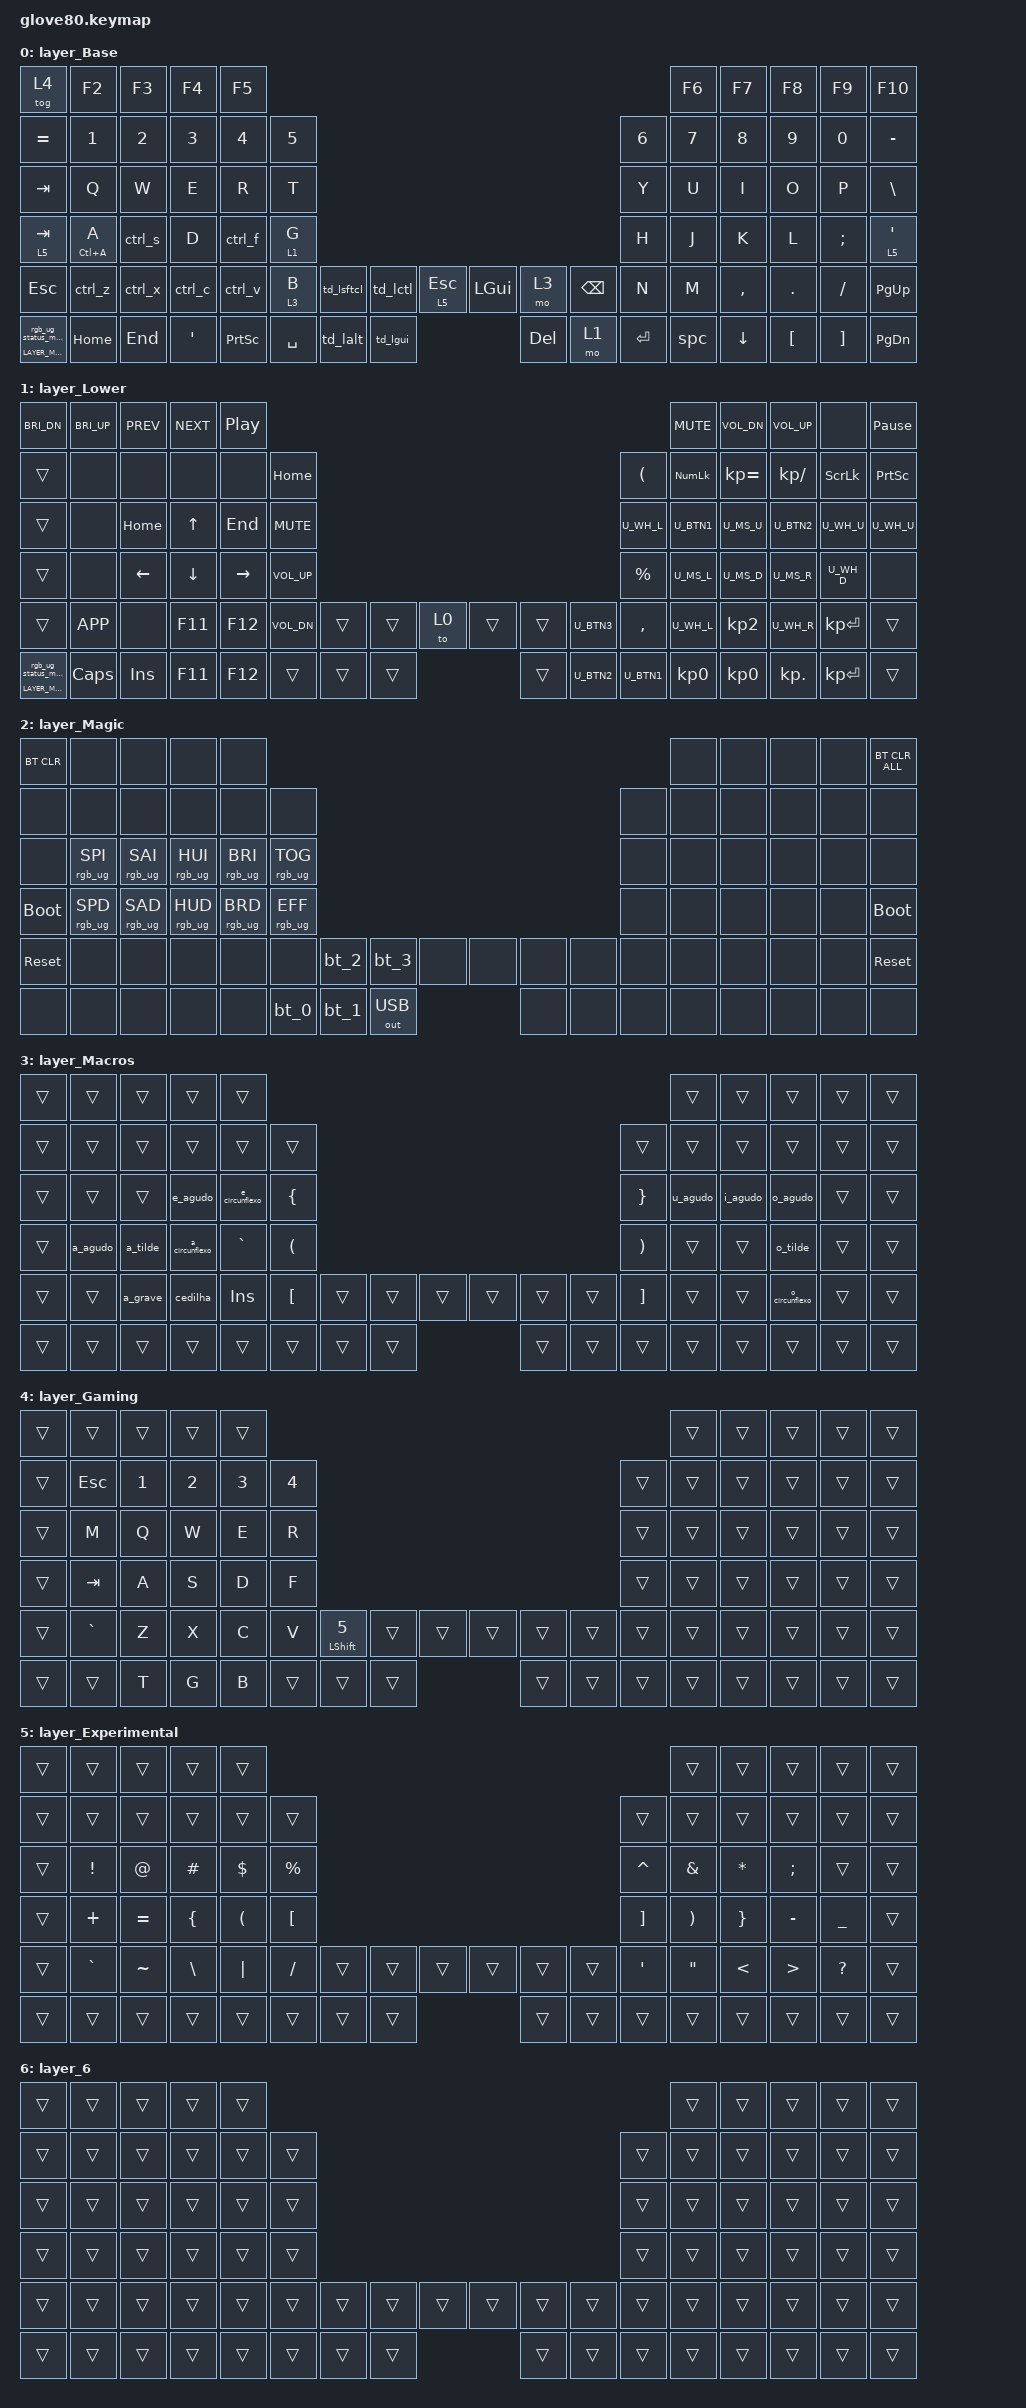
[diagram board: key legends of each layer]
/*
 * Copyright (c) 2020 The ZMK Contributors
 * Copyright (c) 2022 Innaworks Development Limited, trading as MoErgo
 * adding shenanigans
 * SPDX-License-Identifier: MIT
 */


/* THIS FILE WAS GENERATED BY GLOVE80 LAYOUT EDITOR
 *
 * This file was generated automatically. You may or may not want to
 * edit it directly.
 */
/* adding anything just to build it */
#include <behaviors.dtsi>
#include <dt-bindings/zmk/outputs.h>

/* Include behaviour includes needed by key binds - automatically generated */
#include <dt-bindings/zmk/keys.h>
#include <dt-bindings/zmk/ext_power.h>
#include <dt-bindings/zmk/bt.h>
#include <dt-bindings/zmk/rgb.h>
#include <dt-bindings/zmk/outputs.h>

#include "./zmk-nodefree-config/helper.h"
#include "./zmk-nodefree-config/keypos_def/keypos_glv80.h"

#include "./mouse.dtsi"


/* Automatically generated layer name #define */
#define LAYER_Base 0
#define LAYER_Lower 1
#define LAYER_Magic 2
#define LAYER_Macros 3
#define LAYER_Gaming 4
#define LAYER_Experimental 5
#define LAYER_6 6

/ {
    /* Glove80 system behavior & macros */
    behaviors {
        // For the "layer" key, it'd nice to be able to use it as either a shift or a toggle.
        // Configure it as a tap dance, so the first tap (or hold) is a &mo and the second tap is a &to
        lower: lower {
            compatible = "zmk,behavior-tap-dance";
            label = "LAYER_TAP_DANCE";
            #binding-cells = <0>;
            tapping-term-ms = <200>;
            bindings = <&mo LAYER_Lower>, <&to LAYER_Lower>;
        };
    };
};

/ {
    macros {
        rgb_ug_status_macro: rgb_ug_status_macro {
            label = "RGB_UG_STATUS";
            compatible = "zmk,behavior-macro";
            #binding-cells = <0>;
            bindings
                = <&rgb_ug RGB_STATUS>;
        };

        bt_0: bt_0 {
            label = "BT_0";
            compatible = "zmk,behavior-macro";
            #binding-cells = <0>;
            bindings
                = <&out OUT_BLE>,
                  <&bt BT_SEL 0>;
        };

        bt_1: bt_1 {
            label = "BT_1";
            compatible = "zmk,behavior-macro";
            #binding-cells = <0>;
            bindings
                = <&out OUT_BLE>,
                  <&bt BT_SEL 1>;
        };

        bt_2: bt_2 {
            label = "BT_2";
            compatible = "zmk,behavior-macro";
            #binding-cells = <0>;
            bindings
                = <&out OUT_BLE>,
                  <&bt BT_SEL 2>;
        };

        bt_3: bt_3 {
            label = "BT_3";
            compatible = "zmk,behavior-macro";
            #binding-cells = <0>;
            bindings
                = <&out OUT_BLE>,
                  <&bt BT_SEL 3>;
        };
    };
};

/ {
    magic: magic {
        compatible = "zmk,behavior-hold-tap";
        label = "MAGIC_HOLD_TAP";
        #binding-cells = <2>;
        flavor = "tap-preferred";
        tapping-term-ms = <200>;
        bindings = <&mo>, <&rgb_ug_status_macro>;
    };
};

    /* #define for key positions */
#define POS_LH_T1 52
#define POS_LH_T2 53
#define POS_LH_T3 54
#define POS_LH_T4 69
#define POS_LH_T5 70
#define POS_LH_T6 71
#define POS_LH_C1R2 15
#define POS_LH_C1R3 27
#define POS_LH_C1R4 39
#define POS_LH_C1R5 51
#define POS_LH_C2R1 4
#define POS_LH_C2R2 14
#define POS_LH_C2R3 26
#define POS_LH_C2R4 38
#define POS_LH_C2R5 50
#define POS_LH_C2R6 68
#define POS_LH_C3R1 3
#define POS_LH_C3R2 13
#define POS_LH_C3R3 25
#define POS_LH_C3R4 37
#define POS_LH_C3R5 49
#define POS_LH_C3R6 67
#define POS_LH_C4R1 2
#define POS_LH_C4R2 12
#define POS_LH_C4R3 24
#define POS_LH_C4R4 36
#define POS_LH_C4R5 48
#define POS_LH_C4R6 66
#define POS_LH_C5R1 1
#define POS_LH_C5R2 11
#define POS_LH_C5R3 23
#define POS_LH_C5R4 35
#define POS_LH_C5R5 47
#define POS_LH_C5R6 65
#define POS_LH_C6R1 0
#define POS_LH_C6R2 10
#define POS_LH_C6R3 22
#define POS_LH_C6R4 34
#define POS_LH_C6R5 46
#define POS_LH_C6R6 64
#define POS_RH_T1 57
#define POS_RH_T2 56
#define POS_RH_T3 55
#define POS_RH_T4 74
#define POS_RH_T5 73
#define POS_RH_T6 72
#define POS_RH_C1R2 16
#define POS_RH_C1R3 28
#define POS_RH_C1R4 40
#define POS_RH_C1R5 58
#define POS_RH_C2R1 5
#define POS_RH_C2R2 17
#define POS_RH_C2R3 29
#define POS_RH_C2R4 41
#define POS_RH_C2R5 59
#define POS_RH_C2R6 75
#define POS_RH_C3R1 6
#define POS_RH_C3R2 18
#define POS_RH_C3R3 30
#define POS_RH_C3R4 42
#define POS_RH_C3R5 60
#define POS_RH_C3R6 76
#define POS_RH_C4R1 7
#define POS_RH_C4R2 19
#define POS_RH_C4R3 31
#define POS_RH_C4R4 43
#define POS_RH_C4R5 61
#define POS_RH_C4R6 77
#define POS_RH_C5R1 8
#define POS_RH_C5R2 20
#define POS_RH_C5R3 32
#define POS_RH_C5R4 44
#define POS_RH_C5R5 62
#define POS_RH_C5R6 78
#define POS_RH_C6R1 9
#define POS_RH_C6R2 21
#define POS_RH_C6R3 33
#define POS_RH_C6R4 45
#define POS_RH_C6R5 63
#define POS_RH_C6R6 79

    /* Custom Defined Behaviors */
/ {
    #define CONFIG_BT_PERIPHERAL_PREF_MAX_INT=6;
#define CONFIG_ZMK_KSCAN_DEBOUNCE_PRESS_MS=0;
macros {
        #define COMPOSE_KEY F24

        #define COMPOSE_TAP_2(name, k1, k2) \
            name: name { \
                    label = #name; \
                    compatible = "zmk,behavior-macro"; \
                    #binding-cells = <0>; \
                    wait-ms = <10>; \
                    tap-ms = <10>; \
                    bindings \
                        = <&macro_tap     &kp COMPOSE_KEY &kp k1 &kp k2> \
                        ; \
                };
        // á
        COMPOSE_TAP_2(a_agudo, SQT, A)
        // é
        COMPOSE_TAP_2(e_agudo, SQT, E)
        // í
        COMPOSE_TAP_2(i_agudo, SQT, I)
        // ó
        COMPOSE_TAP_2(o_agudo, SQT, O)
        // ú
        COMPOSE_TAP_2(u_agudo, SQT, U)
        // cedilha
        COMPOSE_TAP_2(cedilha, SQT, C)
        // ã
        COMPOSE_TAP_2(a_tilde, TILDE, A)
        // õ
        COMPOSE_TAP_2(o_tilde, TILDE, O)
        // â
        COMPOSE_TAP_2(a_circunflexo, CARET, A)
        // ê
        COMPOSE_TAP_2(e_circunflexo, CARET, E)
        // ô
        COMPOSE_TAP_2(o_circunflexo, CARET, O)
        // à
        COMPOSE_TAP_2(a_grave, GRAVE, A)
    };
     behaviors {  
        ctrld: ctrld {
            compatible = "zmk,behavior-hold-tap";
            label = "ctrl_a";
            #binding-cells = <2>;          
            flavor = "tap-preferred";
            tapping-term-ms = <180>;
            bindings = <&kp>, <&kp>;
        };
        hl: homerow_layer {
		compatible = "zmk,behavior-hold-tap";
		label = "HOMEROW_LAYER";
		#binding-cells = <2>;
        tapping-term-ms = <250>;
        quick-tap-ms = <125>;
        global-quick-tap;
		flavor = "tap-preferred";
		bindings = <&mo>, <&kp>;
	};
	shift_tap_caps_word: behavior_shift_tap_caps_word {
		compatible = "zmk,behavior-caps-word";
		label = "SHIFT_TAP_CAPS_WORD";
		#binding-cells = <0>;
		continue-list = <UNDERSCORE MINUS BACKSPACE DELETE>;
		mods = <(MOD_LSFT | MOD_RSFT)>;
	};
    skq: sticky_key_quick_release {
        compatible = "zmk,behavior-sticky-key";
        label = "STICKY_KEY_QUICK_RELEASE";
        #binding-cells = <1>;
        bindings = <&kp>;
        release-after-ms = <1000>;
        quick-release;
        ignore-modifiers;
    };
    td_lsftcl: tap_dance_left_shift_caps_lock {
        compatible = "zmk,behavior-tap-dance";
        label = "TAP_DANCE_LEFT_SHIFT_CAPS_LOCK";
        #binding-cells = <0>;
        tapping-term-ms = <300>;
        bindings = <&kp LSHIFT>, <&kp CAPS>;
    };
    td_lsft: tap_dance_left_shift_caps_word {
        compatible = "zmk,behavior-tap-dance";
        label = "TAP_DANCE_LEFT_SHIFT_CAPS_WORD";
        #binding-cells = <0>;
        tapping-term-ms = <300>;
        bindings = <&skq LSHIFT>, <&shift_tap_caps_word>;
    };
    td_rsft: tap_dance_right_shift_caps_word {
        compatible = "zmk,behavior-tap-dance";
        label = "TAP_DANCE_RIGHT_SHIFT_CAPS_WORD";
        #binding-cells = <0>;
        tapping-term-ms = <300>;
        bindings = <&skq RSHIFT>, <&shift_tap_caps_word>;
    };
    td_lctl: tap_dance_left_ctrl {
        compatible = "zmk,behavior-tap-dance";
        label = "TAP_DANCE_LEFT_CTRL";
        #binding-cells = <0>;
        tapping-term-ms = <300>;
        bindings = <&skq LCTRL>, <&skq LS(LCTRL)>;
    };
    td_rctl: tap_dance_right_ctrl {
        compatible = "zmk,behavior-tap-dance";
        label = "TAP_DANCE_RIGHT_CTRL";
        #binding-cells = <0>;
        tapping-term-ms = <300>;
        bindings = <&skq RCTRL>, <&skq LS(RCTRL)>;
    };
    td_lalt: tap_dance_left_alt {
        compatible = "zmk,behavior-tap-dance";
        label = "TAP_DANCE_LEFT_ALT";
        #binding-cells = <0>;
        tapping-term-ms = <300>;
        bindings = <&skq LALT>, <&skq LS(LALT)>;
    };
    td_ralt: tap_dance_right_alt {
        compatible = "zmk,behavior-tap-dance";
        label = "TAP_DANCE_RIGHT_ALT";
        #binding-cells = <0>;
        tapping-term-ms = <300>;
        bindings = <&skq RALT>, <&skq LS(RALT)>;
    };
    td_lgui: tap_dance_left_gui {
        compatible = "zmk,behavior-tap-dance";
        label = "TAP_DANCE_LEFT_GUI";
        #binding-cells = <0>;
        tapping-term-ms = <300>;
        bindings = <&kp LGUI>, <&kp LS(LGUI)>;
    };
    spc: space_underscore {
        compatible = "zmk,behavior-mod-morph";
        label = "SPACE_UNDERSCORE";
        #binding-cells = <0>;
        bindings = <&kp SPACE>, <&kp UNDERSCORE>;
        mods = <(MOD_LSFT|MOD_RSFT)>;
        keep-mods = <(MOD_RSFT)>;
    };
        #define CTRLD_TAP(name, k1) \
            name: name { \
                    label = #name; \
                    compatible = "zmk,behavior-tap-dance"; \
                    #binding-cells = <0>; \
                    tapping-term-ms = <210>; \
                    bindings \
                        = <&ctrld LC(k1) k1 > \
                        ; \
            };
        CTRLD_TAP(ctrl_a, A)
        CTRLD_TAP(ctrl_c, C)
        CTRLD_TAP(ctrl_s, S)
        CTRLD_TAP(ctrl_x, X)
        CTRLD_TAP(ctrl_f, F)
        CTRLD_TAP(ctrl_v, V)
        CTRLD_TAP(ctrl_z, Z)
    };
};

    /* Automatically generated keymap */
/ {
    keymap {
        compatible = "zmk,keymap";


        layer_Base {
            bindings = <
               &tog 4          &kp F2   &kp F3   &kp F4     &kp F5                                                                                &kp F6     &kp F7    &kp F8    &kp F9             &kp F10
            &kp EQUAL          &kp N1   &kp N2   &kp N3     &kp N4   &kp N5                                                               &kp N6  &kp N7     &kp N8    &kp N9    &kp N0           &kp MINUS
              &kp TAB           &kp Q    &kp W    &kp E      &kp R    &kp T                                                                &kp Y   &kp U      &kp I     &kp O     &kp P            &kp BSLH
            &hl 5 TAB  &ctrld LC(A) A  &ctrl_s    &kp D    &ctrl_f  &hl 1 G                                                                &kp H   &kp J      &kp K     &kp L  &kp SEMI  &hl 5 SINGLE_QUOTE
              &kp ESC         &ctrl_z  &ctrl_x  &ctrl_c    &ctrl_v  &hl 3 B  &td_lsftcl  &td_lctl  &hl 5 ESC  &kp LGUI   &mo 3  &kp BSPC   &kp N   &kp M  &kp COMMA   &kp DOT  &kp FSLH           &kp PG_UP
 &magic LAYER_Magic 0        &kp HOME  &kp END  &kp SQT  &kp PSCRN            &kp SPACE  &td_lalt   &td_lgui   &kp DEL   &mo 1   &kp RET            &spc   &kp DOWN  &kp LBKT  &kp RBKT           &kp PG_DN
            >;
        };

        layer_Lower {
            bindings = <
         &kp C_BRI_DN  &kp C_BRI_UP      &kp C_PREV      &kp C_NEXT         &kp C_PP                                                                                       &kp C_MUTE  &kp C_VOL_DN  &kp C_VOL_UP            &none  &kp PAUSE_BREAK
               &trans         &none           &none           &none            &none      &kp HOME                                                   &kp LEFT_PARENTHESIS  &kp KP_NUM  &kp KP_EQUAL  &kp KP_SLASH  &kp SCROLLLOCK  &kp PRINTSCREEN
               &trans         &none        &kp HOME    &kp UP_ARROW          &kp END    &kp C_MUTE                                                    U_WH_L        U_BTN1        U_MS_U       U_BTN2       U_WH_U   U_WH_U
               &trans         &none  &kp LEFT_ARROW  &kp DOWN_ARROW  &kp RIGHT_ARROW  &kp C_VOL_UP                                                    &kp PERCENT   U_MS_L        U_MS_D       U_MS_R        U_WH_D      &none
               &trans     &kp K_APP           &none         &kp F11          &kp F12  &kp C_VOL_DN  &trans  &trans   &to 0  &trans  &trans  U_BTN3    &kp COMMA     U_WH_L        &kp KP_N2    U_WH_R     &kp KP_ENTER       &trans
 &magic LAYER_Magic 0      &kp CAPS         &kp INS         &kp F11          &kp F12                &trans  &trans  &trans  &trans  U_BTN2  U_BTN1             &kp KP_N0     &kp KP_N0    &kp KP_DOT    &kp KP_ENTER      &trans
            >;
        };

        layer_Magic {
            bindings = <
  &bt BT_CLR            &none            &none            &none            &none                                                                                  &none   &none   &none   &none  &bt BT_CLR_ALL
       &none            &none            &none            &none            &none            &none                                                         &none   &none   &none   &none   &none           &none
       &none  &rgb_ug RGB_SPI  &rgb_ug RGB_SAI  &rgb_ug RGB_HUI  &rgb_ug RGB_BRI  &rgb_ug RGB_TOG                                                         &none   &none   &none   &none   &none           &none
 &bootloader  &rgb_ug RGB_SPD  &rgb_ug RGB_SAD  &rgb_ug RGB_HUD  &rgb_ug RGB_BRD  &rgb_ug RGB_EFF                                                         &none   &none   &none   &none   &none     &bootloader
      &sys_reset            &none            &none            &none            &none            &none   &bt_2   &bt_3         &none   &none   &none   &none   &none   &none   &none   &none   &none          &sys_reset
       &none            &none            &none            &none            &none                    &bt_0   &bt_1  &out OUT_USB   &none   &none   &none           &none   &none   &none   &none           &none
            >;
        };

        layer_Macros {
            bindings = <
 &trans    &trans    &trans          &trans          &trans                                                                        &trans    &trans          &trans  &trans  &trans
 &trans    &trans    &trans          &trans          &trans    &trans                                                    &trans    &trans    &trans          &trans  &trans  &trans
 &trans    &trans    &trans        &e_agudo  &e_circunflexo  &kp LBRC                                                  &kp RBRC  &u_agudo  &i_agudo        &o_agudo  &trans  &trans
 &trans  &a_agudo  &a_tilde  &a_circunflexo       &kp GRAVE  &kp LPAR                                                  &kp RPAR    &trans    &trans        &o_tilde  &trans  &trans
 &trans    &trans  &a_grave        &cedilha         &kp INS  &kp LBKT  &trans  &trans  &trans  &trans  &trans  &trans  &kp RBKT    &trans    &trans  &o_circunflexo  &trans  &trans
 &trans    &trans    &trans          &trans          &trans            &trans  &trans  &trans  &trans  &trans  &trans              &trans    &trans          &trans  &trans  &trans
            >;
        };

        layer_Gaming {
            bindings = <
 &trans     &trans  &trans  &trans  &trans                                                                        &trans  &trans  &trans  &trans  &trans
 &trans    &kp ESC  &kp N1  &kp N2  &kp N3  &kp N4                                                        &trans  &trans  &trans  &trans  &trans  &trans
 &trans      &kp M   &kp Q   &kp W   &kp E   &kp R                                                        &trans  &trans  &trans  &trans  &trans  &trans
 &trans    &kp TAB   &kp A   &kp S   &kp D   &kp F                                                        &trans  &trans  &trans  &trans  &trans  &trans
 &trans  &kp GRAVE   &kp Z   &kp X   &kp C   &kp V  &mt LSHFT N5  &trans  &trans  &trans  &trans  &trans  &trans  &trans  &trans  &trans  &trans  &trans
 &trans     &trans   &kp T   &kp G   &kp B                &trans  &trans  &trans  &trans  &trans  &trans          &trans  &trans  &trans  &trans  &trans
            >;
        };

        layer_Experimental {
            bindings = <
 &trans     &trans     &trans    &trans    &trans                                                                          &trans    &trans     &trans     &trans  &trans
 &trans     &trans     &trans    &trans    &trans     &trans                                                     &trans    &trans    &trans     &trans     &trans  &trans
 &trans   &kp EXCL     &kp AT  &kp HASH  &kp DLLR  &kp PRCNT                                                  &kp CARET  &kp AMPS  &kp STAR   &kp SEMI     &trans  &trans
 &trans   &kp PLUS  &kp EQUAL  &kp LBRC  &kp LPAR   &kp LBKT                                                   &kp RBKT  &kp RPAR  &kp RBRC  &kp MINUS  &kp UNDER  &trans
 &trans  &kp GRAVE  &kp TILDE  &kp BSLH  &kp PIPE   &kp FSLH  &trans  &trans  &trans  &trans  &trans  &trans    &kp SQT   &kp DQT    &kp LT     &kp GT  &kp QMARK  &trans
 &trans     &trans     &trans    &trans    &trans             &trans  &trans  &trans  &trans  &trans  &trans               &trans    &trans     &trans     &trans  &trans
            >;
        };

        layer_6 {
            bindings = <
 &trans  &trans  &trans  &trans  &trans                                                                  &trans  &trans  &trans  &trans  &trans
 &trans  &trans  &trans  &trans  &trans  &trans                                                  &trans  &trans  &trans  &trans  &trans  &trans
 &trans  &trans  &trans  &trans  &trans  &trans                                                  &trans  &trans  &trans  &trans  &trans  &trans
 &trans  &trans  &trans  &trans  &trans  &trans                                                  &trans  &trans  &trans  &trans  &trans  &trans
 &trans  &trans  &trans  &trans  &trans  &trans  &trans  &trans  &trans  &trans  &trans  &trans  &trans  &trans  &trans  &trans  &trans  &trans
 &trans  &trans  &trans  &trans  &trans          &trans  &trans  &trans  &trans  &trans  &trans          &trans  &trans  &trans  &trans  &trans
            >;
        };

    };
};
